AUTOSAR XML (schema 4-3-0)
package /Impl_SWC_DKC_ARPkg
  swc implementation Impl_SWC_DKC_type: programming-language=C, sw-version=1.0.0, vendor-id=0, behavior=SWC_DKC_type_IB
    code-descriptors:
      code SRC: artifact-descriptors=autosar-engineering-object={short-label=EngObject, category=SWSRC}
    resource consumption ResourceConsumption
      memory section Mem_SWC_DKC_CODE: size=0, sw-addrmethod=CODE, symbol=CODE
package /Impl_Type_DKC_ARPkg
  impl type u8Array8_DKCData_type: category=ARRAY
    element u8_DKCData: category=VALUE, array-size=8, array-size-semantics=FIXED-SIZE, base-type=uint8
  impl type u8Array25_UWBStatusData_type: category=ARRAY
    element u8_UWBStatusData: category=VALUE, array-size=25, array-size-semantics=FIXED-SIZE, base-type=uint8
package /Interface_DKC_ARPkg
  client server interface IF_DKCCDD
    operation CSOP_DKCGetData
      arg u8Array8_DKCData: type=u8Array8_DKCData_type, direction=OUT, server-argument-impl-policy=USE-ARGUMENT-TYPE
    operation CSOP_UWBGetStatusData
      arg u8Array25_UWBStatusData: type=u8Array25_UWBStatusData_type, direction=OUT, server-argument-impl-policy=USE-ARGUMENT-TYPE
  sender receiver interface IF_DKCData
    data u8Array8_DKCData: type=u8Array8_DKCData_type
  sender receiver interface IF_UWBStatusData
    data u8Array25_UWBStatusData: type=u8Array25_UWBStatusData_type
package /SWC_DKC_ARPkg
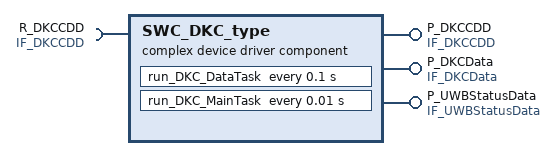
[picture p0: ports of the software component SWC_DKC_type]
  complex device driver sw component type SWC_DKC_type
    provide port P_DKCCDD: provided-interface=IF_DKCCDD
    provide port P_DKCData: provided-interface=IF_DKCData
    provide port P_UWBStatusData: provided-interface=IF_UWBStatusData
    require port R_DKCCDD: required-interface=IF_DKCCDD
    behavior SWC_DKC_type_IB: handle-termination-and-restart=NO-SUPPORT, port-api-option{enable-take-address=false, indirect-api=false, port=P_DKCCDD}
      timing event TE_DKC_100ms: start-on-event=run_DKC_DataTask, period=0.1
      timing event TE_DKC_10ms: start-on-event=run_DKC_MainTask, period=0.01
      operation invoked event oie_P_DKCCDD_CSOP_DKCGetData: start-on-event=run_DKCGetData, operation=P_DKCCDD.CSOP_DKCGetData
      operation invoked event oie_P_DKCCDD_CSOP_UWBGetStatusData: start-on-event=run_UWBGetStatusData, operation=P_DKCCDD.CSOP_UWBGetStatusData
      4 x runnable:
        run_DKCGetData
        run_UWBGetStatusData
        run_DKC_DataTask
          data-send-points:
            access dsp_u8Array8_DKCData: accessed-variable=P_DKCData.u8Array8_DKCData
            access dsp_u8Array25_UWBStatusData: accessed-variable=P_UWBStatusData.u8Array25_UWBStatusData
          sync call scp_CSOP_DKCGetData: operation=R_DKCCDD.CSOP_DKCGetData, timeout=0.0
          sync call scp_CSOP_UWBGetStatusData: operation=R_DKCCDD.CSOP_UWBGetStatusData, timeout=0.0
        run_DKC_MainTask
